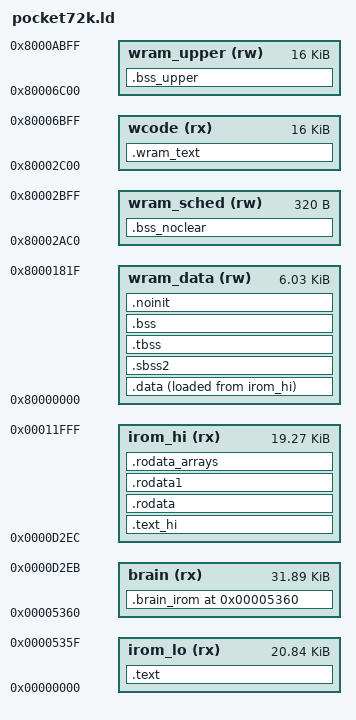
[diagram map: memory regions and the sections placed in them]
/* ################################################################################################# */
/* # << NEORV32 - RISC-V GCC Linker Script >>                                                      # */
/* # ********************************************************************************************* # */
/* # BSD 3-Clause License                                                                          # */
/* #                                                                                               # */
/* # Copyright (c) 2020, Stephan Nolting. All rights reserved.                                     # */
/* #                                                                                               # */
/* # Redistribution and use in source and binary forms, with or without modification, are          # */
/* # permitted provided that the following conditions are met:                                     # */
/* #                                                                                               # */
/* # 1. Redistributions of source code must retain the above copyright notice, this list of        # */
/* #    conditions and the following disclaimer.                                                   # */
/* #                                                                                               # */
/* # 2. Redistributions in binary form must reproduce the above copyright notice, this list of     # */
/* #    conditions and the following disclaimer in the documentation and/or other materials        # */
/* #    provided with the distribution.                                                            # */
/* #                                                                                               # */
/* # 3. Neither the name of the copyright holder nor the names of its contributors may be used to  # */
/* #    endorse or promote products derived from this software without specific prior written      # */
/* #    permission.                                                                                # */
/* #                                                                                               # */
/* # THIS SOFTWARE IS PROVIDED BY THE COPYRIGHT HOLDERS AND CONTRIBUTORS "AS IS" AND ANY EXPRESS   # */
/* # OR IMPLIED WARRANTIES, INCLUDING, BUT NOT LIMITED TO, THE IMPLIED WARRANTIES OF               # */
/* # MERCHANTABILITY AND FITNESS FOR A PARTICULAR PURPOSE ARE DISCLAIMED. IN NO EVENT SHALL THE    # */
/* # COPYRIGHT HOLDER OR CONTRIBUTORS BE LIABLE FOR ANY DIRECT, INDIRECT, INCIDENTAL, SPECIAL,     # */
/* # EXEMPLARY, OR CONSEQUENTIAL DAMAGES (INCLUDING, BUT NOT LIMITED TO, PROCUREMENT OF SUBSTITUTE # */
/* # GOODS OR SERVICES; LOSS OF USE, DATA, OR PROFITS; OR BUSINESS INTERRUPTION) HOWEVER CAUSED    # */
/* # AND ON ANY THEORY OF LIABILITY, WHETHER IN CONTRACT, STRICT LIABILITY, OR TORT (INCLUDING     # */
/* # NEGLIGENCE OR OTHERWISE) ARISING IN ANY WAY OUT OF THE USE OF THIS SOFTWARE, EVEN IF ADVISED  # */
/* # OF THE POSSIBILITY OF SUCH DAMAGE.                                                            # */
/* # ********************************************************************************************* # */
/* # The NEORV32 Processor - https://github.com/stnolting/neorv32              (c) Stephan Nolting # */
/* ################################################################################################# */

/* Copyright (C) 2014-2020 Free Software Foundation, Inc.
   Copying and distribution of this script, with or without modification,
   are permitted in any medium without royalty provided the copyright
   notice and this notice are preserved.  */

/* paprium-fw: GENERATED by tools/mkld.py from board/pocket/link/pocket72k.json - edit the JSON, not this file.
   Layout pocket72k: IROM 72 KB (rom0 32 KB + extension 40 KB), brain hole 0x5360-0xD2EB,
   WRAM 48 KB. See docs/LAYOUT.md. */
/* Changes: Copyright (C) 2026 Marsupial Solutions LLC (GPL-3.0-or-later) */

OUTPUT_FORMAT("elf32-littleriscv", "elf32-littleriscv", "elf32-littleriscv")
OUTPUT_ARCH(riscv)
ENTRY(_start)

MEMORY
{
  irom_lo    (rx) : ORIGIN = 0x00000000, LENGTH = 0x5360
  brain      (rx) : ORIGIN = 0x00005360, LENGTH = 0x7F8C
  irom_hi    (rx) : ORIGIN = 0x0000D2EC, LENGTH = 0x4D14
  wram_data  (rw) : ORIGIN = 0x80000000, LENGTH = 0x1820
  wram_sched (rw) : ORIGIN = 0x80002AC0, LENGTH = 0x140
  wcode      (rx) : ORIGIN = 0x80002C00, LENGTH = 0x4000
  wram_upper (rw) : ORIGIN = 0x80006C00, LENGTH = 0x4000
}
/* brain_data 0x80001820-0x80002ABF is the brain's own (fixed by its link): no output section may use it.
   stack 0x8000AC00-0x8000BFFF: crt0 loads sp from __crt0_stack_begin. */

SECTIONS
{
  __crt0_stack_begin = 0x8000BFFC;
  __stack_floor = 0x8000AC00;

  /* the WRAM code window: the brain's counting helpers (cf.bin, linked at 0x80002C00 when the brain was built)
     first, then the glue. Before .text so that these input sections are taken here, not by .text's wildcards. */
  .wram_text :
  {
    PROVIDE(__wram_text_start = .);
    KEEP(*(.wram_cf))
    . = ALIGN(4);
    *zz_buddy.c.o(.text .text.* .rodata .rodata.* .srodata .srodata.*)
    *zz_buddy_brain.c.o(.text .text.* .rodata .rodata.* .srodata .srodata.*)
    *zz_buddy_trap.c.o(.text.zz_buddy_trap .text.zz_buddy_call)
    *s1_glue.c.o(.text .text.* .rodata .rodata.* .srodata .srodata.*)
    *sfx_s1.c.o(.text .text.* .rodata .rodata.* .srodata .srodata.*)
    *s1_cache4b.c.o(.text .text.* .rodata .rodata.* .srodata .srodata.*)
    . = ALIGN(4);
    PROVIDE(__wram_text_end = .);
  } > wcode

  /* firmware code listed for the IROM above the brain. Before .text so that .text's wildcards do not take it. */
  .text_hi :
  {
    PROVIDE(__text_hi_start = .);
    *paprium.c.o(.text.ppm_reset)
    *paprium.c.o(.text.ppm_init_cmd_ptr)
    *mame.c.o(.text.ppm_chip_preload)
    *mdp.c.o(.text.mdp_init)
    *appinit.c.o(.text .text.*)
    *bootpage.c.o(.text .text.*)
    *bodies_s1.c.o(.text .text.*)
    *vu_s1.c.o(.text .text.*)
    *disp.c.o(.text .text.*)
    *jobs.c.o(.text .text.*)
    *wdog.c.o(.text .text.*)
    *fatal.c.o(.text .text.*)
    *mcureset.c.o(.text .text.*)
    *stats.c.o(.text .text.*)
    *dbgsave.c.o(.text .text.*)
    *audio_s1.c.o(.text .text.*)
    . = ALIGN(4);
    PROVIDE(__text_hi_end = .);
  } > irom_hi

  .text :
  {
    PROVIDE(__text_start = .);
    PROVIDE(__textstart = .);
    PROVIDE_HIDDEN (__rela_iplt_start = .);
    *(.rela.iplt)
    PROVIDE_HIDDEN (__rela_iplt_end = .);
    *(.rela.plt)
    KEEP(*(.text.boot)); /* crt0: start-up code at the beginning of the IROM */
    KEEP (*(SORT_NONE(.init)))
    *(.text.unlikely .text.*_unlikely .text.unlikely.*)
    *(.text.exit .text.exit.*)
    *(.text.startup .text.startup.*)
    *(.text.hot .text.hot.*)
    *(SORT(.text.sorted.*))
    *(.text .stub .text.* .gnu.linkonce.t.*)
    *(.gnu.warning)
    KEEP (*(SORT_NONE(.fini)))
    KEEP (*crtbegin.o(.ctors))
    KEEP (*crtbegin?.o(.ctors))
    KEEP (*(EXCLUDE_FILE (*crtend.o *crtend?.o ) .ctors))
    KEEP (*(SORT(.ctors.*)))
    KEEP (*(.ctors))
    KEEP (*crtbegin.o(.dtors))
    KEEP (*crtbegin?.o(.dtors))
    KEEP (*(EXCLUDE_FILE (*crtend.o *crtend?.o ) .dtors))
    KEEP (*(SORT(.dtors.*)))
    KEEP (*(.dtors))
    . = ALIGN(4);
    PROVIDE (__etext = .);
    PROVIDE (_etext = .);
    PROVIDE (etext = .);
  } > irom_lo

  /* read-only data */
  .rodata         : { *(.rodata .rodata.* .gnu.linkonce.r.*) } > irom_hi
  .rodata1        : { *(.rodata1) } > irom_hi
  .rodata_arrays :
  {
    PROVIDE_HIDDEN (__init_array_start = .);
    KEEP (*(SORT_BY_INIT_PRIORITY(.init_array.*) SORT_BY_INIT_PRIORITY(.ctors.*)))
    KEEP (*(.init_array EXCLUDE_FILE (*crtbegin.o *crtbegin?.o *crtend.o *crtend?.o ) .ctors))
    PROVIDE_HIDDEN (__init_array_end = .);
    PROVIDE_HIDDEN (__fini_array_start = .);
    KEEP (*(SORT_BY_INIT_PRIORITY(.fini_array.*) SORT_BY_INIT_PRIORITY(.dtors.*)))
    KEEP (*(.fini_array EXCLUDE_FILE (*crtbegin.o *crtbegin?.o *crtend.o *crtend?.o ) .dtors))
    PROVIDE_HIDDEN (__fini_array_end = .);
    . = ALIGN(4);
  } > irom_hi

  /* initialised read/write data: runs in WRAM, its image sits in the IROM, crt0 copies it */
  .data :
  {
    __DATA_BEGIN__ = .;
    __SDATA_BEGIN__ = .;
    *(.sdata2 .sdata2.* .gnu.linkonce.s2.*)
    *(.data .data.* .gnu.linkonce.d.*)
    SORT(CONSTRUCTORS)
    *(.srodata.cst16) *(.srodata.cst8) *(.srodata.cst4) *(.srodata.cst2) *(.srodata .srodata.*)
    *(.sdata .sdata.* .gnu.linkonce.s.*)
    PROVIDE_HIDDEN (__tdata_start = .);
    *(.tdata .tdata.* .gnu.linkonce.td.*)
    . = ALIGN(4);
    _edata = .; PROVIDE (edata = .);
    . = .;
  } > wram_data AT > irom_hi

  .sbss2          : { *(.sbss2 .sbss2.* .gnu.linkonce.sb2.*) } > wram_data
  .tbss           : { *(.tbss .tbss.* .gnu.linkonce.tb.*) *(.tcommon) } > wram_data

  /* .bss objects whose initial contents are never read: in the scheduler gap, NOT cleared by crt0 (outside
     __bss_start..__BSS_END__). Before .bss so that .bss's wildcards do not take them. */
  .bss_noclear (NOLOAD) :
  {
    PROVIDE(__bss_noclear_start = .);
    *mame.c.o(.bss.ppm_chip_list)
    *mame.c.o(.bss.ppm_drawList)
    *paprium.c.o(.bss.ppmio)
    *mame.c.o(.bss.snap_da_other)
    *mame.c.o(.sbss.snap_db_ring)
    *spr_posts.c.o(.bss.spr_list_addr)
    . = ALIGN(4);
    PROVIDE(__bss_noclear_end = .);
  } > wram_sched

  .bss (NOLOAD) :
  {
    __bss_start = .;
    *(.dynsbss)
    *(.sbss .sbss.* .gnu.linkonce.sb.*)
    *(.scommon)
    *(.dynbss)
    *(.bss .bss.* .gnu.linkonce.b.*)
    PROVIDE_HIDDEN (__preinit_array_start = .);
    KEEP (*(.preinit_array))
    PROVIDE_HIDDEN (__preinit_array_end = .);
    *(COMMON)
    . = ALIGN(. != 0 ? 32 / 8 : 1);
    . = ALIGN(32 / 8);
    __BSS_END__ = .;
    __global_pointer$ = MIN(__SDATA_BEGIN__ + 0x800,
                            MAX(__DATA_BEGIN__ + 0x800, __BSS_END__ - 0x800));
    _end = .; PROVIDE (end = .);
  } > wram_data

  /* the buddy glue's state: not cleared by crt0 (zz_buddy.c clears it at the first event of a boot) */
  .noinit (NOLOAD) :
  {
    *(.noinit.zz_buddy)
    *(.noinit .noinit.*)
    . = ALIGN(16);
    PROVIDE(__noinit_end = .);
  } > wram_data

  /* the s1 images: .bss objects placed in wram_upper (input sections .bss_upper.*); the s1 crt0 clears them */
  .bss_upper (NOLOAD) :
  {
    PROVIDE(__bss_upper_start = .);
    *(.bss_upper .bss_upper.*)
    . = ALIGN(4);
    PROVIDE(__bss_upper_end = .);
  } > wram_upper

  /* the CPU MATE brain (rodata + text, assembled for 0x5360): bytes never relinked */
  .brain_irom 0x5360 :
  {
    PROVIDE(__brain_irom_start = .);
    KEEP(*(.brain_irom .brain_irom.*))
    . = ALIGN(4);
    PROVIDE(__brain_irom_end = .);
  } > brain

  ASSERT(__brain_irom_start == 0x5360 && __brain_irom_end == 0xD2EC,
         "paprium-fw: the brain must fill 0x5360-0xD2EB exactly (bytes unchanged)")
  ASSERT(ADDR(.wram_text) == 0x80002C00, "paprium-fw: cf.bin must sit at the code window's start")
  ASSERT(ADDR(.text) == 0, "paprium-fw: crt0 (.text.boot) must start the IROM")
  ASSERT(__noinit_end <= 0x80001820, "paprium-fw: firmware data runs into the brain's data")
  ASSERT(__wram_text_end <= 0x80006C00, "paprium-fw: the code window overflows")
  ASSERT(__bss_upper_start % 4 == 0 && __bss_upper_end % 4 == 0, "paprium-fw: .bss_upper must be word-aligned (crt0 clears it by words)")

  /* debug sections (not loaded) */
  .stab          0 : { *(.stab) }
  .stabstr       0 : { *(.stabstr) }
  .comment       0 : { *(.comment) }
  .gnu.build.attributes : { *(.gnu.build.attributes .gnu.build.attributes.*) }
  .debug          0 : { *(.debug) }
  .line           0 : { *(.line) }
  .debug_srcinfo  0 : { *(.debug_srcinfo) }
  .debug_sfnames  0 : { *(.debug_sfnames) }
  .debug_aranges  0 : { *(.debug_aranges) }
  .debug_pubnames 0 : { *(.debug_pubnames) }
  .debug_info     0 : { *(.debug_info .gnu.linkonce.wi.*) }
  .debug_abbrev   0 : { *(.debug_abbrev) }
  .debug_line     0 : { *(.debug_line .debug_line.* .debug_line_end) }
  .debug_frame    0 : { *(.debug_frame) }
  .debug_str      0 : { *(.debug_str) }
  .debug_loc      0 : { *(.debug_loc) }
  .debug_macinfo  0 : { *(.debug_macinfo) }
  .debug_pubtypes 0 : { *(.debug_pubtypes) }
  .debug_ranges   0 : { *(.debug_ranges) }
  .debug_macro    0 : { *(.debug_macro) }
  .debug_addr     0 : { *(.debug_addr) }
  .gnu.attributes 0 : { KEEP (*(.gnu.attributes)) }
  /DISCARD/ : { *(.note.GNU-stack) *(.gnu_debuglink) *(.gnu.lto_*) }

  /* symbols for crt0 */
  PROVIDE(__crt0_upper_bss_start = __bss_upper_start);
  PROVIDE(__crt0_upper_bss_end   = __bss_upper_end);
  PROVIDE(__crt0_bss_start   = __bss_start);
  PROVIDE(__crt0_bss_end     = __BSS_END__);
  PROVIDE(__crt0_copy_data_src_begin = LOADADDR(.data));
  PROVIDE(__crt0_copy_data_dst_begin = __DATA_BEGIN__);
  PROVIDE(__crt0_copy_data_dst_end   = __DATA_BEGIN__ + SIZEOF(.data));
}
